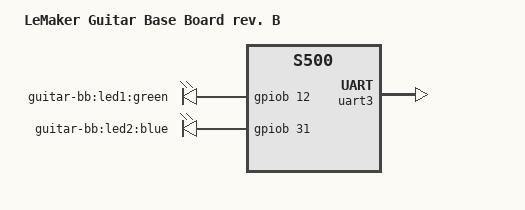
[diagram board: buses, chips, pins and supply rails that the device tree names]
/*
 * Copyright (c) 2016-2017 Andreas Färber
 *
 * SPDX-License-Identifier: (GPL-2.0+ OR MIT)
 */

/dts-v1/;

#include <dt-bindings/gpio/gpio.h>

#include "owl-s500-guitar.dtsi"

/ {
	compatible = "lemaker,guitar-bb-rev-b", "lemaker,guitar", "actions,s500";
	model = "LeMaker Guitar Base Board rev. B";

	aliases {
		serial3 = &uart3;
	};

	chosen {
		stdout-path = "serial3:115200n8";
	};

	leds {
		compatible = "gpio-leds";
		pinctrl-names = "default";
		pinctrl-0 = <&lcd0_lvds_o_pn_pins>;

		led1 {
			label = "guitar-bb:led1:green";
			gpios = <&gpiob 12 GPIO_ACTIVE_HIGH>;
			linux,default-trigger = "heartbeat";
		};

		led2 {
			label = "guitar-bb:led2:blue";
			gpios = <&gpiob 31 GPIO_ACTIVE_HIGH>;
			linux,default-trigger = "heartbeat";
		};
	};

	uart3_clk: uart3-clk {
		compatible = "fixed-clock";
		clock-frequency = <921600>;
		#clock-cells = <0>;
	};
};

&uart3 {
	status = "okay";
	clocks = <&uart3_clk>;
};
